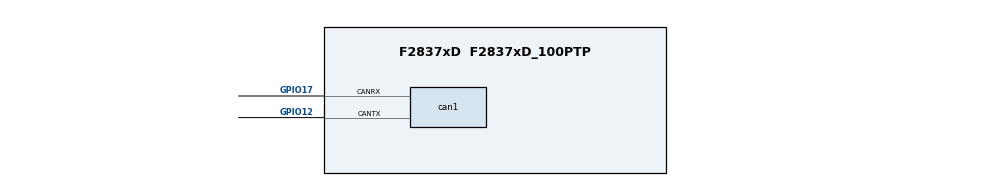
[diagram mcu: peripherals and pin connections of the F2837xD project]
/**
 * @cliArgs --device "F2837xD" --package "F2837xD_100PTP" --part "F2837xD_100PTP" --context "CPU1" --product "C2000WARE@5.02.00.00"
 * @versions {"tool":"1.15.0+2826"}
 */

/**
 * Import the modules used in this configuration.
 */
const can    = scripting.addModule("/driverlib/can.js", {}, false);
const can1   = can.addInstance();
const flash  = scripting.addModule("/driverlib/flash.js", {}, false);
const flash1 = flash.addInstance();

/**
 * Write custom configuration values to the imported modules.
 */
can1.$name                = "DiagCAN";
can1.msgObjsUsed          = [31,32];
can1.can.$assign          = "CANB";
can1.can.canrxPin.$assign = "GPIO17";
can1.can.cantxPin.$assign = "GPIO12";
can1.msgObj31.$name       = "msgObj0";
can1.msgObj31.msgLen      = 8;
can1.msgObj31.msgID       = 1793;
can1.msgObj32.$name       = "msgObj1";
can1.msgObj32.msgID       = 1794;
can1.msgObj32.msgType     = "CAN_MSG_OBJ_TYPE_TX";
can1.msgObj32.msgLen      = 8;

flash1.$name = "UserFMC0";
